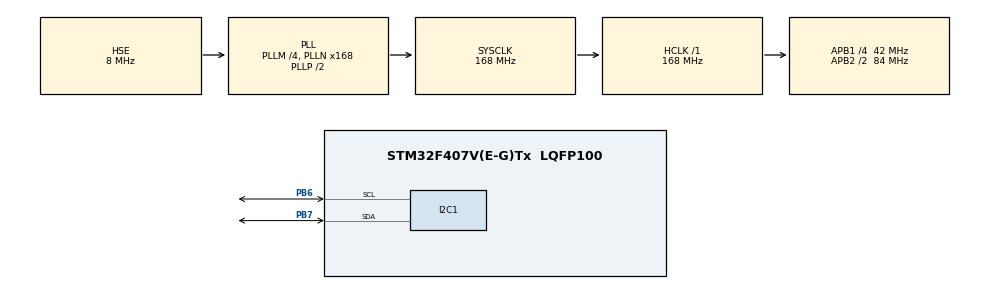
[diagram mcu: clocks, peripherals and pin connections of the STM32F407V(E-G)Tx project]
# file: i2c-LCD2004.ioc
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Mcu.Family=STM32F4
Mcu.Name=STM32F407V(E-G)Tx
Mcu.Package=LQFP100
NVIC.PriorityGroup=NVIC_PRIORITYGROUP_4
PA13.Mode=Serial_Wire
PA13.Signal=SYS_JTMS-SWDIO
PA14.Mode=Serial_Wire
PA14.Signal=SYS_JTCK-SWCLK
PB6.Mode=I2C
PB6.Signal=I2C1_SCL
PB7.Mode=I2C
PB7.Signal=I2C1_SDA
PH0-OSC_IN.Mode=HSE-External-Oscillator
PH0-OSC_IN.Signal=RCC_OSC_IN
PH1-OSC_OUT.Mode=HSE-External-Oscillator
PH1-OSC_OUT.Signal=RCC_OSC_OUT
ProjectManager.HeapSize=0x200
ProjectManager.StackSize=0x400
ProjectManager.TargetToolchain=MDK-ARM V5.32
RCC.48MHZClocksFreq_Value=84000000
RCC.AHBFreq_Value=168000000
RCC.APB1CLKDivider=RCC_HCLK_DIV4
RCC.APB1Freq_Value=42000000
RCC.APB1TimFreq_Value=84000000
RCC.APB2CLKDivider=RCC_HCLK_DIV2
RCC.APB2Freq_Value=84000000
RCC.APB2TimFreq_Value=168000000
RCC.CortexFreq_Value=168000000
RCC.HCLKFreq_Value=168000000
RCC.HSE_VALUE=8000000
RCC.HSI_VALUE=16000000
RCC.LSE_VALUE=32768
RCC.PLLM=4
RCC.PLLN=168
RCC.PLLSourceVirtual=RCC_PLLSOURCE_HSE
RCC.SYSCLKFreq_VALUE=168000000
RCC.SYSCLKSource=RCC_SYSCLKSOURCE_PLLCLK
RCC.VCOOutputFreq_Value=336000000
board=custom

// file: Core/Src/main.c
/* USER CODE BEGIN Header */
/**
  ******************************************************************************
  * @file           : main.c
  * @brief          : Main program body
  ******************************************************************************
  * @attention
  *
  * Copyright (c) 2023 STMicroelectronics.
  * All rights reserved.
  *
  * This software is licensed under terms that can be found in the LICENSE file
  * in the root directory of this software component.
  * If no LICENSE file comes with this software, it is provided AS-IS.
  *
  ******************************************************************************
  */
/* USER CODE END Header */
#include "main.h"
#include "i2c.h"
#include "gpio.h"

/* USER CODE BEGIN Includes */
#include "i2c-lcd.h"
#include <stdio.h>
/* USER CODE END Includes */

/* USER CODE BEGIN PV */
char cc1[] = {0x00, 0x00, 0x0A, 0x00, 0x11, 0x0E, 0x00, 0x00};  // smiley
char cc2[] = {0x0E, 0x0E, 0x04, 0x0E, 0x15, 0x04, 0x0A, 0x0A};  // Robo
char cc3[] = {0x08, 0x0C, 0x0E, 0x0F, 0x0E, 0x0C, 0x08, 0x00};  // arrow
char cc4[] = {0x00, 0x04, 0x0E, 0x0E, 0x0E, 0x1F, 0x04, 0x00};  // bell
char cc5[] = {0x00, 0x00, 0x0A, 0x15, 0x11, 0x0E, 0x04, 0x00};  // Heart
char cc6[] = {0x00, 0x0E, 0x11, 0x11, 0x11, 0x0A, 0x1B, 0x00};  // omega
char cc7[] = {0x0E, 0x10, 0x17, 0x12, 0x12, 0x12, 0x10, 0x0E};  // CT
char cc8[] = {0x04, 0x04, 0x1F, 0x04, 0x04, 0x00, 0x1F, 0x00};  // +-
/* USER CODE END PV */

void SystemClock_Config(void);

int main(void)
{

  /* MCU Configuration--------------------------------------------------------*/

  /* Reset of all peripherals, Initializes the Flash interface and the Systick. */
  HAL_Init();

  /* Configure the system clock */
  SystemClock_Config();

  /* Initialize all configured peripherals */
  MX_GPIO_Init();
  MX_I2C1_Init();
  /* USER CODE BEGIN 2 */
	for(int i=1; i<128; i++)
	{
			int ret = HAL_I2C_IsDeviceReady(&hi2c1, (uint16_t)(i<<1), 3, 5);
			if (ret != HAL_OK) /* No ACK Received At That Address */
			{
					printf("- \n");
			}
			else if(ret == HAL_OK)
			{
				printf("HAL_I2C_IsDeviceReady: 0x%X \n",i);

			}
	}

  lcd_init ();
	HAL_Delay(100);

	// store the chars into the CGRAM
  lcd_send_cmd(0x40);
  for (int i=0; i<8; i++) lcd_send_data(cc1[i]);

  lcd_send_cmd(0x40+8);
  for (int i=0; i<8; i++) lcd_send_data(cc2[i]);

  lcd_send_cmd(0x40+16);
  for (int i=0; i<8; i++) lcd_send_data(cc3[i]);

  lcd_send_cmd(0x40+24);
  for (int i=0; i<8; i++) lcd_send_data(cc4[i]);

  lcd_send_cmd(0x40+32);
  for (int i=0; i<8; i++) lcd_send_data(cc5[i]);

  lcd_send_cmd(0x40+40);
  for (int i=0; i<8; i++) lcd_send_data(cc6[i]);

  lcd_send_cmd(0x40+48);
  for (int i=0; i<8; i++) lcd_send_data(cc7[i]);

  lcd_send_cmd(0x40+56);
  for (int i=0; i<8; i++) lcd_send_data(cc8[i]);

  /* USER CODE END 2 */

  /* Infinite loop */
  while (1)
  {

    /* USER CODE BEGIN 3 */
//		for(int i = 0; i<20; i++)
//		{
//			lcd_put_cur(0, i);
//			//lcd_send_string ("a");
//			lcd_send_data(89);
//			HAL_Delay(500);
//			lcd_clear ();
//		}
//

//			lcd_put_cur(1, 0);

//			lcd_send_string("bangnguyendev hi");

//			HAL_Delay(2000);

		lcd_put_cur(1, 0);
		for (int i=0; i<8; i++) lcd_send_data(i);

		HAL_Delay(1000);
		//lcd_send_cmd(0x0E);
		//HAL_Delay(500);
		lcd_clear ();

  }
  /* USER CODE END 3 */
}

void SystemClock_Config(void)
{
  RCC_OscInitTypeDef RCC_OscInitStruct = {0};
  RCC_ClkInitTypeDef RCC_ClkInitStruct = {0};

  /** Configure the main internal regulator output voltage
  */
  __HAL_RCC_PWR_CLK_ENABLE();
  __HAL_PWR_VOLTAGESCALING_CONFIG(PWR_REGULATOR_VOLTAGE_SCALE1);

  /** Initializes the RCC Oscillators according to the specified parameters
  * in the RCC_OscInitTypeDef structure.
  */
  RCC_OscInitStruct.OscillatorType = RCC_OSCILLATORTYPE_HSE;
  RCC_OscInitStruct.HSEState = RCC_HSE_ON;
  RCC_OscInitStruct.PLL.PLLState = RCC_PLL_ON;
  RCC_OscInitStruct.PLL.PLLSource = RCC_PLLSOURCE_HSE;
  RCC_OscInitStruct.PLL.PLLM = 4;
  RCC_OscInitStruct.PLL.PLLN = 168;
  RCC_OscInitStruct.PLL.PLLP = RCC_PLLP_DIV2;
  RCC_OscInitStruct.PLL.PLLQ = 4;
  if (HAL_RCC_OscConfig(&RCC_OscInitStruct) != HAL_OK)
  {
    Error_Handler();
  }

  /** Initializes the CPU, AHB and APB buses clocks
  */
  RCC_ClkInitStruct.ClockType = RCC_CLOCKTYPE_HCLK|RCC_CLOCKTYPE_SYSCLK
                              |RCC_CLOCKTYPE_PCLK1|RCC_CLOCKTYPE_PCLK2;
  RCC_ClkInitStruct.SYSCLKSource = RCC_SYSCLKSOURCE_PLLCLK;
  RCC_ClkInitStruct.AHBCLKDivider = RCC_SYSCLK_DIV1;
  RCC_ClkInitStruct.APB1CLKDivider = RCC_HCLK_DIV4;
  RCC_ClkInitStruct.APB2CLKDivider = RCC_HCLK_DIV2;

  if (HAL_RCC_ClockConfig(&RCC_ClkInitStruct, FLASH_LATENCY_5) != HAL_OK)
  {
    Error_Handler();
  }
}

void Error_Handler(void)
{
  __disable_irq();
  while (1)
  {
  }
}
